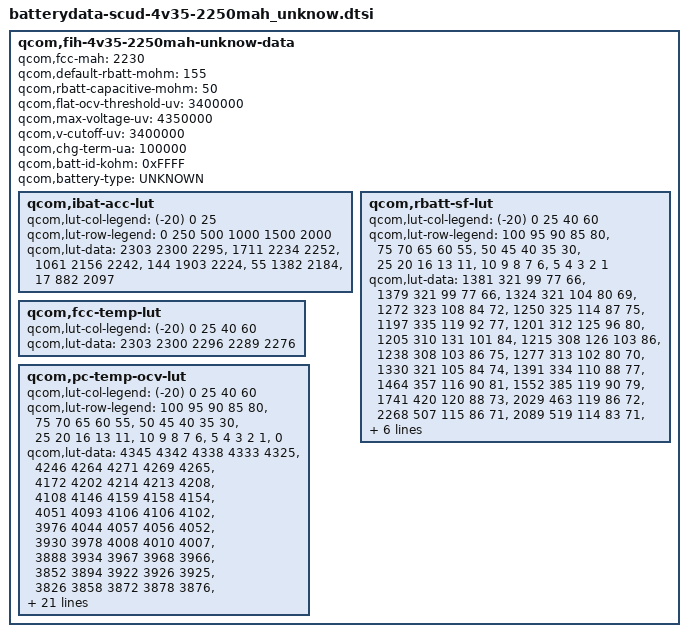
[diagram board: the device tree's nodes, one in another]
/* Copyright (c) 2014, The Linux Foundation. All rights reserved.
 *
 * This program is free software; you can redistribute it and/or modify
 * it under the terms of the GNU General Public License version 2 and
 * only version 2 as published by the Free Software Foundation.
 *
 * This program is distributed in the hope that it will be useful,
 * but WITHOUT ANY WARRANTY; without even the implied warranty of
 * MERCHANTABILITY or FITNESS FOR A PARTICULAR PURPOSE.  See the
 * GNU General Public License for more details.
 */

qcom,fih-4v35-2250mah-unknow-data {
	qcom,fcc-mah = <2230>;
	qcom,default-rbatt-mohm = <155>;
	qcom,rbatt-capacitive-mohm = <50>;	
	qcom,flat-ocv-threshold-uv = <3400000>;
	qcom,max-voltage-uv = <4350000>;
	qcom,v-cutoff-uv = <3400000>;
	qcom,chg-term-ua = <100000>;
	qcom,batt-id-kohm = <0xFFFF>;
	qcom,battery-type = "UNKNOWN";

	qcom,ibat-acc-lut {
		qcom,lut-col-legend = <(-20) 0 25>;
		qcom,lut-row-legend = <0 250 500 1000 1500 2000>;
		qcom,lut-data = <2303 2300 2295>,
				<1711 2234 2252>,
				<1061 2156 2242>,
				<144 1903 2224>,
				<55 1382 2184>,
				<17 882 2097>;
	};

	qcom,rbatt-sf-lut {
		qcom,lut-col-legend = <(-20) 0 25 40 60>;
		qcom,lut-row-legend = <100 95 90 85 80>,
				<75 70 65 60 55>,
				<50 45 40 35 30>,
				<25 20 16 13 11>,
				<10 9 8 7 6>,
				<5 4 3 2 1>;
		qcom,lut-data = <1381 321 99 77 66>,
				<1379 321 99 77 66>,
				<1324 321 104 80 69>,
				<1272 323 108 84 72>,
				<1250 325 114 87 75>,
				<1197 335 119 92 77>,
				<1201 312 125 96 80>,
				<1205 310 131 101 84>,
				<1215 308 126 103 86>,
				<1238 308 103 86 75>,
				<1277 313 102 80 70>,
				<1330 321 105 84 74>,
				<1391 334 110 88 77>,
				<1464 357 116 90 81>,
				<1552 385 119 90 79>,
				<1741 420 120 88 73>,
				<2029 463 119 86 72>,
				<2268 507 115 86 71>,
				<2089 519 114 83 71>,
				<2312 543 120 88 74>,
				<2492 564 125 90 76>,
				<2699 588 131 94 77>,
				<2970 613 136 97 77>,
				<3282 643 142 97 77>,
				<3688 672 142 94 74>,
				<4183 702 139 92 75>,
				<4890 745 145 95 77>,
				<5829 801 158 105 88>,
				<7364 882 177 115 92>,
				<11465 1178 206 133 112>;
	};

	qcom,fcc-temp-lut {
		qcom,lut-col-legend = <(-20) 0 25 40 60>;
		qcom,lut-data = <2303 2300 2296 2289 2276>;
	};

	qcom,pc-temp-ocv-lut {
		qcom,lut-col-legend = <(-20) 0 25 40 60>;
		qcom,lut-row-legend = <100 95 90 85 80>,
				<75 70 65 60 55>,
				<50 45 40 35 30>,
				<25 20 16 13 11>,
				<10 9 8 7 6>,
				<5 4 3 2 1>,
				<0>;
		qcom,lut-data = <4345 4342 4338 4333 4325>,
				<4246 4264 4271 4269 4265>,
				<4172 4202 4214 4213 4208>,
				<4108 4146 4159 4158 4154>,
				<4051 4093 4106 4106 4102>,
				<3976 4044 4057 4056 4052>,
				<3930 3978 4008 4010 4007>,
				<3888 3934 3967 3968 3966>,
				<3852 3894 3922 3926 3925>,
				<3826 3858 3872 3878 3876>,
				<3804 3830 3842 3844 3842>,
				<3786 3804 3818 3820 3819>,
				<3771 3786 3798 3800 3799>,
				<3756 3772 3782 3782 3782>,
				<3741 3761 3770 3766 3762>,
				<3724 3746 3756 3750 3736>,
				<3706 3728 3735 3727 3712>,
				<3686 3710 3704 3697 3682>,
				<3669 3697 3687 3680 3668>,
				<3654 3688 3684 3678 3666>,
				<3645 3684 3682 3676 3666>,
				<3634 3680 3680 3674 3664>,
				<3622 3675 3678 3672 3661>,
				<3606 3666 3674 3666 3654>,
				<3586 3650 3657 3648 3630>,
				<3558 3621 3622 3612 3590>,
				<3523 3574 3572 3562 3540>,
				<3472 3514 3508 3500 3476>,
				<3398 3432 3427 3417 3390>,
				<3266 3305 3306 3288 3256>,
				<3000 3000 3000 3000 3000>;
	};
};
